# SF32LB57x register map
File version: 1.0
CPU: CM33 r0p1, little endian, MPU, FPU, 3 interrupt priority bits
Registers are 32-bit, read-write, reset 0x0 unless marked. A register's access mark holds for its fields unless they carry their own. Offsets are from the block's base; [hi:lo] are bit positions; {n}, {i} and the like mark numbered series.

## HPSYS_SECU
Base 0x50002000
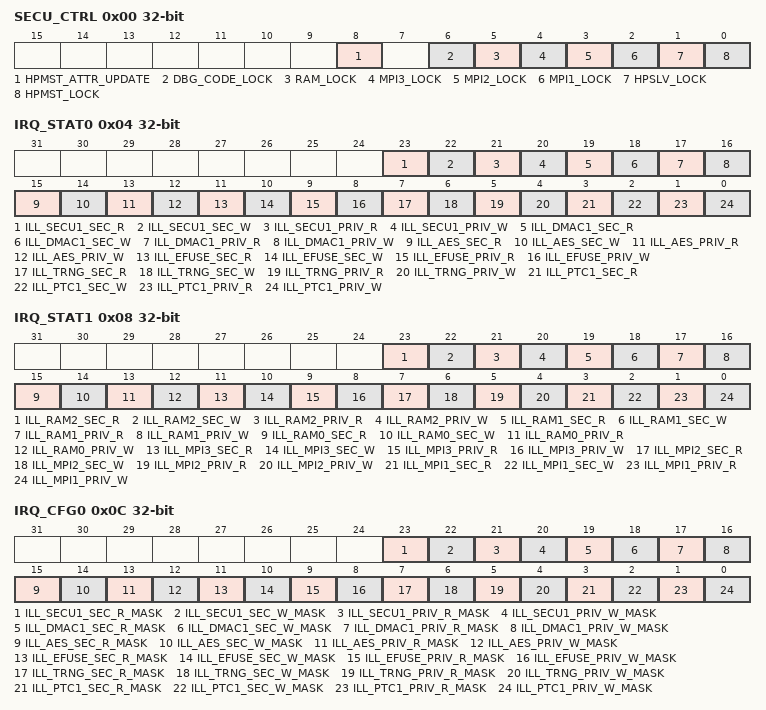
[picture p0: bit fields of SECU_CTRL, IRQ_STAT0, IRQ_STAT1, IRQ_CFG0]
0x00 SECU_CTRL
  [8] HPMST_ATTR_UPDATE — write 1 to update HPMST_ATTR config to each master
  [6] DBG_CODE_LOCK — write 1 to lock dbg_code
  [5] RAM_LOCK — write 1 to lock RAM config
  [4] MPI3_LOCK — write 1 to lock MPI3 config
  [3] MPI2_LOCK — write 1 to lock MPI2 config
  [2] MPI1_LOCK — write 1 to lock MPI1 config
  [1] HPSLV_LOCK — write 1 to lock HPSLV_ATTR config
  [0] HPMST_LOCK — write 1 to lock HPMST_ATTR config
0x04 IRQ_STAT0
  [23] ILL_SECU1_SEC_R
  [22] ILL_SECU1_SEC_W
  [21] ILL_SECU1_PRIV_R
  [20] ILL_SECU1_PRIV_W
  [19] ILL_DMAC1_SEC_R
  [18] ILL_DMAC1_SEC_W
  [17] ILL_DMAC1_PRIV_R
  [16] ILL_DMAC1_PRIV_W
  [15] ILL_AES_SEC_R
  [14] ILL_AES_SEC_W
  [13] ILL_AES_PRIV_R
  [12] ILL_AES_PRIV_W
  [11] ILL_EFUSE_SEC_R
  [10] ILL_EFUSE_SEC_W
  [9] ILL_EFUSE_PRIV_R
  [8] ILL_EFUSE_PRIV_W
  [7] ILL_TRNG_SEC_R
  [6] ILL_TRNG_SEC_W
  [5] ILL_TRNG_PRIV_R
  [4] ILL_TRNG_PRIV_W
  [3] ILL_PTC1_SEC_R
  [2] ILL_PTC1_SEC_W
  [1] ILL_PTC1_PRIV_R
  [0] ILL_PTC1_PRIV_W — write 1 to clear the interrupt
0x08 IRQ_STAT1
  [23] ILL_RAM2_SEC_R
  [22] ILL_RAM2_SEC_W
  [21] ILL_RAM2_PRIV_R
  [20] ILL_RAM2_PRIV_W
  [19] ILL_RAM1_SEC_R
  [18] ILL_RAM1_SEC_W
  [17] ILL_RAM1_PRIV_R
  [16] ILL_RAM1_PRIV_W
  [15] ILL_RAM0_SEC_R
  [14] ILL_RAM0_SEC_W
  [13] ILL_RAM0_PRIV_R
  [12] ILL_RAM0_PRIV_W
  [11] ILL_MPI3_SEC_R
  [10] ILL_MPI3_SEC_W
  [9] ILL_MPI3_PRIV_R
  [8] ILL_MPI3_PRIV_W
  [7] ILL_MPI2_SEC_R
  [6] ILL_MPI2_SEC_W
  [5] ILL_MPI2_PRIV_R
  [4] ILL_MPI2_PRIV_W
  [3] ILL_MPI1_SEC_R
  [2] ILL_MPI1_SEC_W
  [1] ILL_MPI1_PRIV_R
  [0] ILL_MPI1_PRIV_W — write 1 to clear the interrupt
0x0C IRQ_CFG0
  [23] ILL_SECU1_SEC_R_MASK
  [22] ILL_SECU1_SEC_W_MASK
  [21] ILL_SECU1_PRIV_R_MASK
  [20] ILL_SECU1_PRIV_W_MASK
  [19] ILL_DMAC1_SEC_R_MASK
  [18] ILL_DMAC1_SEC_W_MASK
  [17] ILL_DMAC1_PRIV_R_MASK
  [16] ILL_DMAC1_PRIV_W_MASK
  [15] ILL_AES_SEC_R_MASK
  [14] ILL_AES_SEC_W_MASK
  [13] ILL_AES_PRIV_R_MASK
  [12] ILL_AES_PRIV_W_MASK
  [11] ILL_EFUSE_SEC_R_MASK
  [10] ILL_EFUSE_SEC_W_MASK
  [9] ILL_EFUSE_PRIV_R_MASK
  [8] ILL_EFUSE_PRIV_W_MASK
  [7] ILL_TRNG_SEC_R_MASK
  [6] ILL_TRNG_SEC_W_MASK
  [5] ILL_TRNG_PRIV_R_MASK
  [4] ILL_TRNG_PRIV_W_MASK
  [3] ILL_PTC1_SEC_R_MASK
  [2] ILL_PTC1_SEC_W_MASK
  [1] ILL_PTC1_PRIV_R_MASK
  [0] ILL_PTC1_PRIV_W_MASK — 0: mask the interrupt
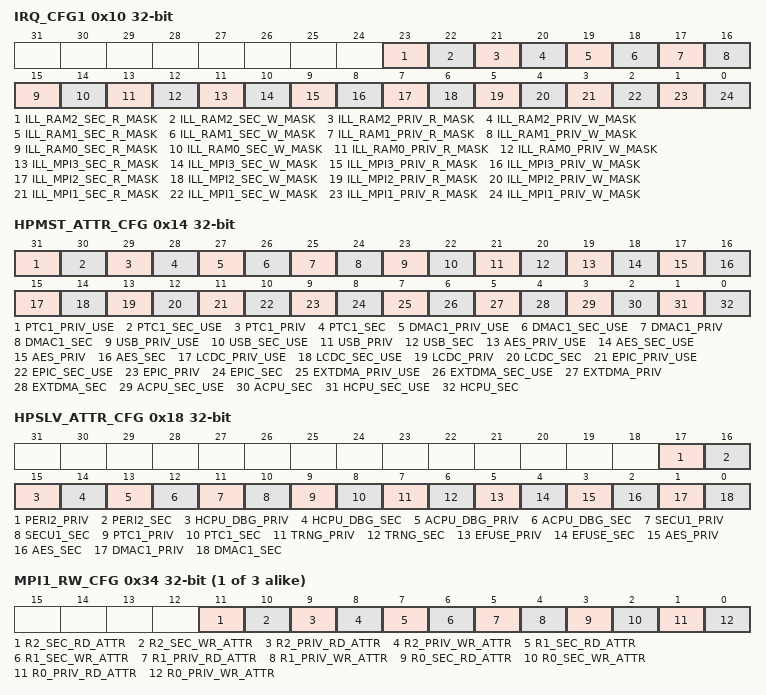
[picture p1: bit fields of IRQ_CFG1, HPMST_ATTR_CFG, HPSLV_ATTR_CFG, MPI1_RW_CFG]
0x10 IRQ_CFG1
  [23] ILL_RAM2_SEC_R_MASK
  [22] ILL_RAM2_SEC_W_MASK
  [21] ILL_RAM2_PRIV_R_MASK
  [20] ILL_RAM2_PRIV_W_MASK
  [19] ILL_RAM1_SEC_R_MASK
  [18] ILL_RAM1_SEC_W_MASK
  [17] ILL_RAM1_PRIV_R_MASK
  [16] ILL_RAM1_PRIV_W_MASK
  [15] ILL_RAM0_SEC_R_MASK
  [14] ILL_RAM0_SEC_W_MASK
  [13] ILL_RAM0_PRIV_R_MASK
  [12] ILL_RAM0_PRIV_W_MASK
  [11] ILL_MPI3_SEC_R_MASK
  [10] ILL_MPI3_SEC_W_MASK
  [9] ILL_MPI3_PRIV_R_MASK
  [8] ILL_MPI3_PRIV_W_MASK
  [7] ILL_MPI2_SEC_R_MASK
  [6] ILL_MPI2_SEC_W_MASK
  [5] ILL_MPI2_PRIV_R_MASK
  [4] ILL_MPI2_PRIV_W_MASK
  [3] ILL_MPI1_SEC_R_MASK
  [2] ILL_MPI1_SEC_W_MASK
  [1] ILL_MPI1_PRIV_R_MASK
  [0] ILL_MPI1_PRIV_W_MASK — 0: mask the interrupt
0x14 HPMST_ATTR_CFG
  [31] PTC1_PRIV_USE — set 1 to use ptc1_priv as ptc1 master interface priviledge attribute
  [30] PTC1_SEC_USE — set 1 to use ptc1_sec as ptc1 master interface secure attribute
  [29] PTC1_PRIV — priviledge attribute 0: non priviledge 1: priviledge
  [28] PTC1_SEC — secure attribute 0: non secure 1: secure
  [27] DMAC1_PRIV_USE — set 1 to use dmac1_priv as dmac1 master interface priviledge attribute
  [26] DMAC1_SEC_USE — set 1 to use dmac1_sec as dmac1 master interface secure attribute
  [25] DMAC1_PRIV — priviledge attribute 0: non priviledge 1: priviledge
  [24] DMAC1_SEC — secure attribute 0: non secure 1: secure
  [23] USB_PRIV_USE — set 1 to use usb_priv as usb master interface priviledge attribute
  [22] USB_SEC_USE — set 1 to use usb_sec as usb master interface secure attribute
  [21] USB_PRIV — priviledge attribute 0: non priviledge 1: priviledge
  [20] USB_SEC — secure attribute 0: non secure 1: secure
  [19] AES_PRIV_USE — set 1 to use aes_priv as aes master interface priviledge attribute
  [18] AES_SEC_USE — set 1 to use aes_sec as aes master interface secure attribute
  [17] AES_PRIV — priviledge attribute 0: non priviledge 1: priviledge
  [16] AES_SEC — secure attribute 0: non secure 1: secure
  [15] LCDC_PRIV_USE — set 1 to use lcdc_priv as lcdc master interface priviledge attribute
  [14] LCDC_SEC_USE — set 1 to use lcdc_sec as lcdc master interface priviledge attribute
  [13] LCDC_PRIV — priviledge attribute 0: non priviledge 1: priviledge
  [12] LCDC_SEC — secure attribute 0: non secure 1: secure
  [11] EPIC_PRIV_USE — set 1 to use epic_priv as epic master interface priviledge attribute
  [10] EPIC_SEC_USE — set 1 to use epic_sec as epic master interface secure attribute
  [9] EPIC_PRIV — priviledge attribute 0: non priviledge 1: priviledge
  [8] EPIC_SEC — secure attribute 0: non secure 1: secure
  [7] EXTDMA_PRIV_USE — set 1 to use extdma_priv as extdma master interface priviledge attribute
  [6] EXTDMA_SEC_USE — set 1 to use extdma_sec as extdma master interface secure attribute
  [5] EXTDMA_PRIV — priviledge attribute 0: non priviledge 1: priviledge
  [4] EXTDMA_SEC — secure attribute 0: non secure 1: secure
  [3] ACPU_SEC_USE — set 1 to use hcpu_sec as acpu master interface secure attribute
  [2] ACPU_SEC — secure attribute 0: non secure 1: secure
  [1] HCPU_SEC_USE — set 1 to use hcpu_sec as hcpu master interface secure attribute
  [0] HCPU_SEC — secure attribute 0: non secure 1: secure
0x18 HPSLV_ATTR_CFG
  [17] PERI2_PRIV — priviledge attribute 0: non priviledge 1: priviledge
  [16] PERI2_SEC — secure attribute 0: non secure 1: secure
  [15] HCPU_DBG_PRIV — priviledge attribute 0: non priviledge 1: priviledge
  [14] HCPU_DBG_SEC — secure attribute 0: non secure 1: secure
  [13] ACPU_DBG_PRIV — priviledge attribute 0: non priviledge 1: priviledge
  [12] ACPU_DBG_SEC — secure attribute 0: non secure 1: secure
  [11] SECU1_PRIV — priviledge attribute 0: non priviledge 1: priviledge
  [10] SECU1_SEC — secure attribute 0: non secure 1: secure
  [9] PTC1_PRIV — priviledge attribute 0: non priviledge 1: priviledge
  [8] PTC1_SEC — secure attribute 0: non secure 1: secure
  [7] TRNG_PRIV — priviledge attribute 0: non priviledge 1: priviledge
  [6] TRNG_SEC — secure attribute 0: non secure 1: secure
  [5] EFUSE_PRIV — priviledge attribute 0: non priviledge 1: priviledge
  [4] EFUSE_SEC — secure attribute 0: non secure 1: secure
  [3] AES_PRIV — priviledge attribute 0: non priviledge 1: priviledge
  [2] AES_SEC — secure attribute 0: non secure 1: secure
  [1] DMAC1_PRIV — priviledge attribute 0: non priviledge 1: priviledge
  [0] DMAC1_SEC — secure attribute 0: non secure 1: secure
{0x0+0x1C*i} MPI{i}_R0_CFG0 (i=1..3)
  [31:10] ST_ADDR
{0x4+0x1C*i} MPI{i}_R0_CFG1 (i=1..3)
  [31:10] END_ADDR
{0x8+0x1C*i} MPI{i}_R1_CFG0 (i=1..3)
  [31:10] ST_ADDR
{0xC+0x1C*i} MPI{i}_R1_CFG1 (i=1..3)
  [31:10] END_ADDR
{0x10+0x1C*i} MPI{i}_R2_CFG0 (i=1..3)
  [31:10] ST_ADDR
{0x14+0x1C*i} MPI{i}_R2_CFG1 (i=1..3)
  [31:10] END_ADDR
{0x18+0x1C*i} MPI{i}_RW_CFG (i=1..3)
  [11] R2_SEC_RD_ATTR — region2 secure read attribute
  [10] R2_SEC_WR_ATTR — region2 secure write attribute
  [9] R2_PRIV_RD_ATTR — region2 priviledge read attribute
  [8] R2_PRIV_WR_ATTR — region2 priviledge write attribute
  [7] R1_SEC_RD_ATTR — region1 secure read attribute
  [6] R1_SEC_WR_ATTR — region1 secure write attribute
  [5] R1_PRIV_RD_ATTR — region1 priviledge read attribute
  [4] R1_PRIV_WR_ATTR — region1 priviledge write attribute
  [3] R0_SEC_RD_ATTR — region0 secure read attribute
  [2] R0_SEC_WR_ATTR — region0 secure write attribute
  [1] R0_PRIV_RD_ATTR — region0 priviledge read attribute
  [0] R0_PRIV_WR_ATTR — region0 priviledge write attribute
{0x70+0x14*i} RAM{i}_R0_CFG0 (i=0..2)
  [31:2] ST_ADDR
{0x74+0x14*i} RAM{i}_R0_CFG1 (i=0..2)
  [31:2] END_ADDR
{0x78+0x14*i} RAM{i}_R1_CFG0 (i=0..2)
  [31:2] ST_ADDR
{0x7C+0x14*i} RAM{i}_R1_CFG1 (i=0..2)
  [31:2] END_ADDR
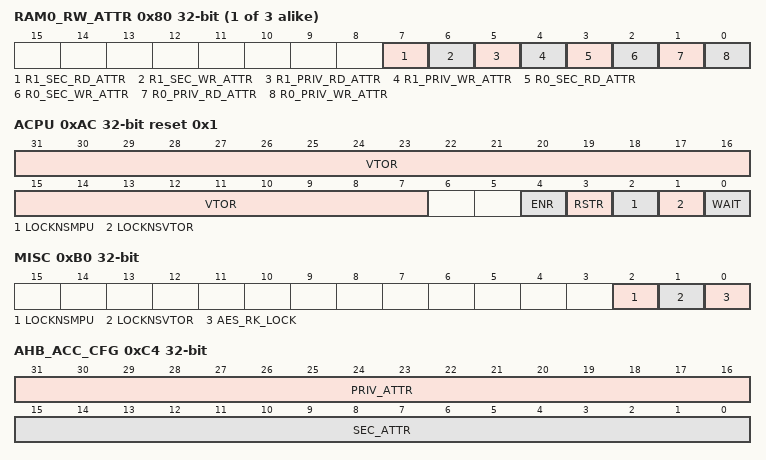
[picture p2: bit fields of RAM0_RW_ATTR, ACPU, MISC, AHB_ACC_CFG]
{0x80+0x14*i} RAM{i}_RW_ATTR (i=0..2)
  [7] R1_SEC_RD_ATTR — region1 secure read attribute
  [6] R1_SEC_WR_ATTR — region1 secure write attribute
  [5] R1_PRIV_RD_ATTR — region1 priviledge read attribute
  [4] R1_PRIV_WR_ATTR — region1 priviledge write attribute
  [3] R0_SEC_RD_ATTR — region0 secure read attribute
  [2] R0_SEC_WR_ATTR — region0 secure write attribute
  [1] R0_PRIV_RD_ATTR — region0 priviledge read attribute
  [0] R0_PRIV_WR_ATTR — region0 priviledge write attribute
0xAC ACPU reset 0x1 — ACPU control
  [31:7] VTOR — vector table offset bit [31:7]
  [4] ENR — write 1 to set module enable, write 0 to disable module
  [3] RSTR — 0 - no reset; 1 - reset
  [2] LOCKNSMPU — set 1 to lock NSMPU of ACPU
  [1] LOCKNSVTOR — set 1 to lock VTOR of ACPU
  [0] WAIT — Stall ACPU out of reset. Write 0 to release ACPU
0xB0 MISC — HCPU control
  [2] LOCKNSMPU — set 1 to lock NSMPU of HCPU
  [1] LOCKNSVTOR — set 1 to lock VTOR of HCPU
  [0] AES_RK_LOCK — 1: disable aes module using rootkey 0: allow aes module using rootkey once this bit is written to 1, it cannot be written to 0 unless reset.
{0xB4+4i} DBG_CODE{i} (i=0..3) — debug code{i}
  [31:0] DATA — used to unlock debug interface
0xC4 AHB_ACC_CFG
  [31:16] PRIV_ATTR — write 1 to set priviledge access check
  [15:0] SEC_ATTR — write 1 to set secure access check bit0: DCMI bit1: MPI1 reg bit2: MPI2 reg bit3: MPI3 reg bit4: PTM1 reg bit5: SDMMC1 reg bit6: SDMMC2 reg bit7: USBC reg bit8: CRC1 reg bit9: GPIO1 reg other: reserved
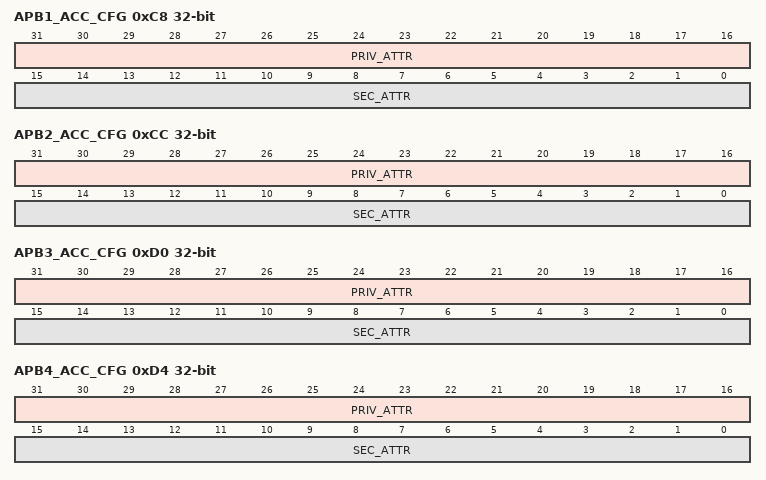
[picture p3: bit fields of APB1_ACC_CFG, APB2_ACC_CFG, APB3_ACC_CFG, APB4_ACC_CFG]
0xC8 APB1_ACC_CFG
  [31:16] PRIV_ATTR — write 1 to set priviledge access check
  [15:0] SEC_ATTR — write 1 to set secure access check bit0: RCC1 reg bit1: JPEGD reg bit2: SECU1 reg bit3: PINMUX1 reg bit4: ATIM1 reg bit5: ATIM2 reg bit6: EZIP reg bit7: EPIC reg bit8: LCDC1 reg bit9: I2S1 reg bit10: CAN1 reg bit11: SYSCFG1 reg bit12: EFUSEC reg bit13: AES reg bit14: CAN2 reg bit15: TRNG reg
0xCC APB2_ACC_CFG
  [31:16] PRIV_ATTR — write 1 to set priviledge access check
  [15:0] SEC_ATTR — write 1 to set secure access check bit1: DMAC1 reg bit2: MAILBOX1 reg bit4: USART1 reg bit5: USART2 reg bit6: USART3 reg bit7: AUDPRC reg bit8: AUDCODEC reg bit9: TSEN reg bit10: I2S2 reg other: reserved
0xD0 APB3_ACC_CFG
  [31:16] PRIV_ATTR — write 1 to set priviledge access check
  [15:0] SEC_ATTR — write 1 to set secure access check bit0: GPTIM1 reg bit2: BTIM1 reg bit4: WDT1 reg bit5: SPI1 reg bit6: SPI2 reg bit10: PDM1 reg bit11: PDM2 reg bit12: I2C1 reg bit13: I2C2 reg bit14: I2C3 reg bit15: I2C4 reg other: reserved
0xD4 APB4_ACC_CFG
  [31:16] PRIV_ATTR — write 1 to set priviledge access check
  [15:0] SEC_ATTR — write 1 to set secure access check bit0: GPTIM2 reg bit1: BTIM2 reg bit2: GPADC reg bit3: PWM1 reg other: reserved
